# LPC55S14 register map
Vendor: nxp.com; File version: 1.0
CPU: CM33 r2p0, little endian, MPU, FPU, VTOR, 3 interrupt priority bits
Registers are 32-bit, read-write, reset 0x0 unless marked. A register's access mark holds for its fields unless they carry their own. Offsets are from the block's base; [hi:lo] are bit positions; lines under a group give offsets from that group; {n}, {i} and the like mark numbered series; 'fields as' and 'values as' point back to an identical list.

## I2S0 — I2S interface
Base 0x40086000; alternate view of FLEXCOMM0
Same registers: I2S1 0x40087000 (alternate view of FLEXCOMM1), I2S2 0x40088000 (alternate view of FLEXCOMM2), I2S3 0x40089000 (alternate view of FLEXCOMM3), I2S4 0x4008A000 (alternate view of FLEXCOMM4), I2S5 0x40096000 (alternate view of FLEXCOMM5), I2S6 0x40097000 (alternate view of FLEXCOMM6), I2S7 0x40098000 (alternate view of FLEXCOMM7)
{0x0+0x20*i} SECCHANNEL[{i}] (i=0..2) group
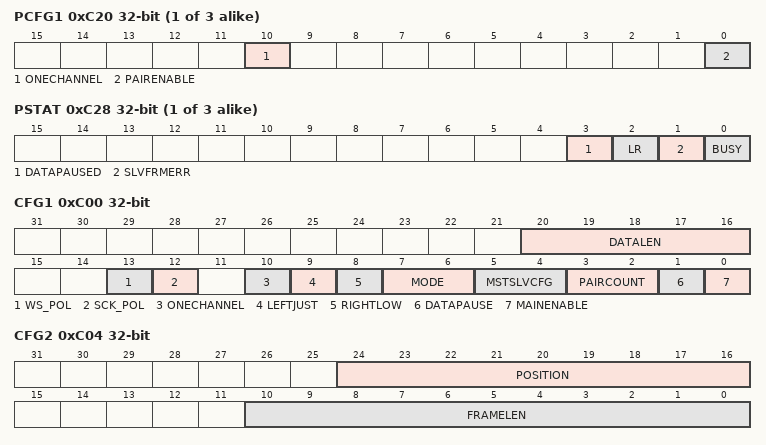
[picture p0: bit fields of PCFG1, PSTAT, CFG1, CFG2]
  0xC20 PCFG1 — Configuration register 1 for channel pair
    [10] ONECHANNEL — Single channel mode.
      0=STEREO (I2S data for this channel pair is treated as left and right channels.); 1=SINGLE (I2S data for this channel pair is treated as a single channel, functionally the left channel for this pair.)
    [0] PAIRENABLE — Enable for this channel pair.
      0=DISABLE (This I2S channel pair is disabled.); 1=ENABLE (This I2S channel pair is enabled.)
  0xC24 PCFG2 — Configuration register 2 for channel pair
    [24:16] POSITION — Data Position.
  0xC28 PSTAT — Status register for channel pair
    [3] DATAPAUSED ro — Data Paused status flag.
      0=PAUSE (Data is not currently paused.); 1=FORCE (A data pause has been requested and is now in force.)
    [2] LR — Left/Right indication.
    [1] SLVFRMERR — Save Frame Error flag.
    [0] BUSY — Busy status for this channel pair.
      0=IDLE (The transmitter/receiver for this channel pair is currently idle.); 1=PROCESSING (The transmitter/receiver for this channel pair is currently processing data.)
0xC00 CFG1 — Configuration register 1 for the primary channel pair.
  [20:16] DATALEN — Data Length, minus 1 encoded, defines the number of data bits to be transmitted or received for all I2S channel pairs in this Flexcomm. Note that data is only driven to or received from SDA for the number of bits defined by DATALEN. DATALEN is also used in these ways by the I2S: Determines the size of data transfers between the FIFO and the I2S serializer/deserializer. See FIFO buffer configurations and usage In mode 1, 2, and 3, determines the location of right data following left data in the frame. In mode 3 (where WS has a one data slot long pulse at the beginning of each data frame) determines the duration of the WS pulse. Values: 0x00 to 0x02 = not supported 0x03 = data is 4 bits in length 0x04 = data is 5 bits in length 0x1F = data is 32 bits in length
  [13] WS_POL — WS polarity.
    0=NOT_INVERTED (Data frames begin at a falling edge of WS (standard for classic I2S).); 1=INVERTED (WS is inverted, resulting in a data frame beginning at a rising edge of WS (standard for most 'non-classic' variations of I2S).)
  [12] SCK_POL — SCK polarity.
    0=FALLING_EDGE (Data is launched on SCK falling edges and sampled on SCK rising edges (standard for I2S).); 1=RISING_EDGE (Data is launched on SCK rising edges and sampled on SCK falling edges.)
  [10] ONECHANNEL — Single channel mode. Applies to both transmit and receive. This configuration bit applies only to the first I2S channel pair. Other channel pairs may select this mode independently in their separate CFG1 registers.
    0=DUAL_CHANNEL (I2S data for this channel pair is treated as left and right channels.); 1=SINGLE_CHANNEL (I2S data for this channel pair is treated as a single channel, functionally the left channel for this pair. In mode 0 only, the right side of the frame begins at POSITION = 0x100. This is because mode 0 makes a clear distinction between the left and right sides of the frame. When ONECHANNEL = 1, the single channel of data may be placed on the right by setting POSITION to 0x100 + the data position within the right side (e.g. 0x108 would place data starting at the 8th clock after the middle of the frame). In other modes, data for the single channel of data is placed at the clock defined by POSITION.)
  [9] LEFTJUST — Left Justify data.
    0=RIGHT_JUSTIFIED (Data is transferred between the FIFO and the I2S serializer/deserializer right justified, i.e. starting from bit 0 and continuing to the position defined by DATALEN. This would correspond to right justified data in the stream on the data bus.); 1=LEFT_JUSTIFIED (Data is transferred between the FIFO and the I2S serializer/deserializer left justified, i.e. starting from the MSB of the FIFO entry and continuing for the number of bits defined by DATALEN. This would correspond to left justified data in the stream on the data bus.)
  [8] RIGHTLOW — Right channel data is in the Low portion of FIFO data. Essentially, this swaps left and right channel data as it is transferred to or from the FIFO. This bit is not used if the data width is greater than 24 bits or if PDMDATA = 1. Note that if the ONECHANNEL field (bit 10 of this register) = 1, the one channel to be used is the nominally the left channel. POSITION can still place that data in the frame where right channel data is normally located. if all enabled channel pairs have ONECHANNEL = 1, then RIGHTLOW = 1 is not allowed.
    0=RIGHT_HIGH (The right channel is taken from the high part of the FIFO data. For example, when data is 16 bits, FIFO bits 31:16 are used for the right channel.); 1=RIGHT_LOW (The right channel is taken from the low part of the FIFO data. For example, when data is 16 bits, FIFO bits 15:0 are used for the right channel.)
  [7:6] MODE — Selects the basic I2S operating mode. Other configurations modify this to obtain all supported cases. See Formats and modes for examples.
    0=CLASSIC_MODE (I2S mode a.k.a. 'classic' mode. WS has a 50% duty cycle, with (for each enabled channel pair) one piece of left channel data occurring during the first phase, and one pieces of right channel data occurring during the second phase. In this mode, the data region begins one clock after the leading WS edge for the frame. For a 50% WS duty cycle, FRAMELEN must define an even number of I2S clocks for the frame. If FRAMELEN defines an odd number of clocks per frame, the extra clock will occur on the right.); 1=DSP_MODE_WS_50_DUTYCYCLE (DSP mode where WS has a 50% duty cycle. See remark for mode 0.); 2=DSP_MODE_WS_1_CLOCK (DSP mode where WS has a one clock long pulse at the beginning of each data frame.); 3=DSP_MODE_WS_1_DATA (DSP mode where WS has a one data slot long pulse at the beginning of each data frame.)
  [5:4] MSTSLVCFG — Master / slave configuration selection, determining how SCK and WS are used by all channel pairs in this Flexcomm.
    0=NORMAL_SLAVE_MODE (Normal slave mode, the default mode. SCK and WS are received from a master and used to transmit or receive data.); 1=WS_SYNC_MASTER (WS synchronized master. WS is received from another master and used to synchronize the generation of SCK, when divided from the Flexcomm function clock.); 2=MASTER_USING_SCK (Master using an existing SCK. SCK is received and used directly to generate WS, as well as transmitting or receiving data.); 3=NORMAL_MASTER (Normal master mode. SCK and WS are generated so they can be sent to one or more slave devices.)
  [3:2] PAIRCOUNT — Provides the number of I2S channel pairs in this Flexcomm This is a read-only field whose value may be different in other Flexcomms. 00 = there is 1 I2S channel pair in this Flexcomm. 01 = there are 2 I2S channel pairs in this Flexcomm. 10 = there are 3 I2S channel pairs in this Flexcomm. 11 = there are 4 I2S channel pairs in this Flexcomm.
    {v}=PAIRS_{v+1} ({v+1} I2S channel pairs in this flexcomm) (v=0..3)
  [1] DATAPAUSE — Data flow Pause. Allows pausing data flow between the I2S serializer/deserializer and the FIFO. This could be done in order to change streams, or while restarting after a data underflow or overflow. When paused, FIFO operations can be done without corrupting data that is in the process of being sent or received. Once a data pause has been requested, the interface may need to complete sending data that was in progress before interrupting the flow of data. Software must check that the pause is actually in effect before taking action. This is done by monitoring the DATAPAUSED flag in the STAT register. When DATAPAUSE is cleared, data transfer will resume at the beginning of the next frame.
    0=NORMAL (Normal operation, or resuming normal operation at the next frame if the I2S has already been paused.); 1=PAUSE (A pause in the data flow is being requested. It is in effect when DATAPAUSED in STAT = 1.)
  [0] MAINENABLE — Main enable for I 2S function in this Flexcomm
    0=DISABLED (All I 2S channel pairs in this Flexcomm are disabled and the internal state machines, counters, and flags are reset. No other channel pairs can be enabled.); 1=ENABLED (This I 2S channel pair is enabled. Other channel pairs in this Flexcomm may be enabled in their individual PAIRENABLE bits.)
0xC04 CFG2 (reset mask 0x1FF01FF) — Configuration register 2 for the primary channel pair.
  [24:16] POSITION — Data Position. Defines the location within the frame of the data for this channel pair. POSITION + DATALEN must be less than FRAMELEN. See Frame format. When MODE = 0, POSITION defines the location of data in both the left phase and right phase, starting one clock after the WS edge. In other modes, POSITION defines the location of data within the entire frame. ONECHANNEL = 1 while MODE = 0 is a special case, see the description of ONECHANNEL. The combination of DATALEN and the POSITION fields of all channel pairs must be made such that the channels do not overlap within the frame. 0x000 = data begins at bit position 0 (the first bit position) within the frame or WS phase. 0x001 = data begins at bit position 1 within the frame or WS phase. 0x002 = data begins at bit position 2 within the frame or WS phase.
  [10:0] FRAMELEN — Frame Length, minus 1 encoded, defines the number of clocks and data bits in the frames that this channel pair participates in. See Frame format. 0x000 to 0x002 = not supported 0x003 = frame is 4 bits in total length 0x004 = frame is 5 bits in total length 0x7FF = frame is 2048 bits in total length if FRAMELEN is an defines an odd length frame (e.g. 33 clocks) in mode 0 or 1, the extra clock appears in the right half. When MODE = 3, FRAMELEN must be larger than DATALEN in order for the WS pulse to be generated correctly.
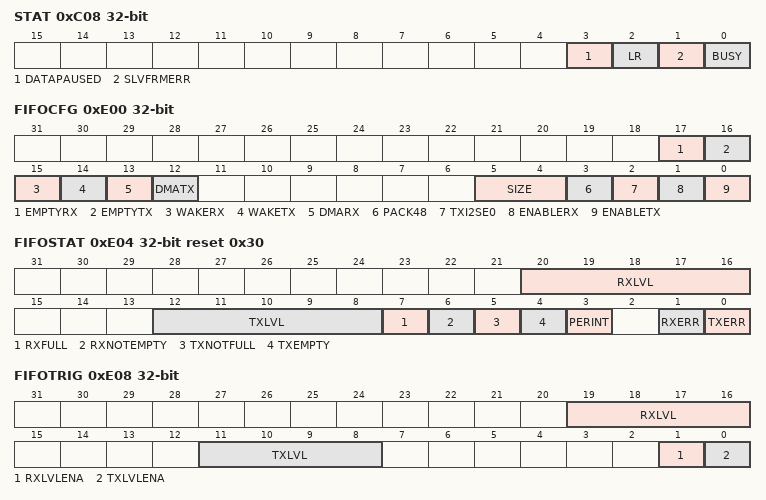
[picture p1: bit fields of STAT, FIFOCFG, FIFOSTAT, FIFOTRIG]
0xC08 STAT (reset mask 0xD) — Status register for the primary channel pair.
  [3] DATAPAUSED ro — Data Paused status flag. Applies to all I2S channels
    0=NOT_PAUSED (Data is not currently paused. A data pause may have been requested but is not yet in force, waiting for an allowed pause point. Refer to the description of the DATAPAUSE control bit in the CFG1 register.); 1=PAUSED (A data pause has been requested and is now in force.)
  [2] LR ro — Left/Right indication. This flag is considered to be a debugging aid and is not expected to be used by an I2S driver. Valid when one channel pair is busy. Indicates left or right data being processed for the currently busy channel pair.
    0=LEFT_CHANNEL; 1=RIGHT_CHANNEL
  [1] SLVFRMERR wo — Slave Frame Error flag. This applies when at least one channel pair is operating as a slave. An error indicates that the incoming WS signal did not transition as expected due to a mismatch between FRAMELEN and the actual incoming I2S stream.
    0=NO_ERROR (No error has been recorded.); 1=ERROR (An error has been recorded for some channel pair that is operating in slave mode. ERROR is cleared by writing a 1 to this bit position.)
  [0] BUSY ro — Busy status for the primary channel pair. Other BUSY flags may be found in the STAT register for each channel pair.
    0=IDLE (The transmitter/receiver for channel pair is currently idle.); 1=BUSY (The transmitter/receiver for channel pair is currently processing data.)
0xC1C DIV — Clock divider, used by all channel pairs.
  [11:0] DIV — This field controls how this I2S block uses the Flexcomm function clock. 0x000 = The Flexcomm function clock is used directly. 0x001 = The Flexcomm function clock is divided by 2. 0x002 = The Flexcomm function clock is divided by 3. 0xFFF = The Flexcomm function clock is divided by 4,096.
0xE00 FIFOCFG (reset mask 0x7F033) — FIFO configuration and enable register.
  [17] EMPTYRX — Empty command for the receive FIFO. When a 1 is written to this bit, the RX FIFO is emptied.
  [16] EMPTYTX — Empty command for the transmit FIFO. When a 1 is written to this bit, the TX FIFO is emptied.
  [15] WAKERX — Wake-up for receive FIFO level. This allows the device to be woken from reduced power modes (up to power-down, as long as the peripheral function works in that power mode) without enabling the TXLVL interrupt. Only DMA wakes up, processes data, and goes back to sleep. The CPU will remain stopped until woken by another cause, such as DMA completion. See Hardware Wake-up control register.
    0=DISABLED (Only enabled interrupts will wake up the device form reduced power modes.); 1=ENABLED (A device wake-up for DMA will occur if the receive FIFO level reaches the value specified by RXLVL in FIFOTRIG, even when the RXLVL interrupt is not enabled.)
  [14] WAKETX — Wake-up for transmit FIFO level. This allows the device to be woken from reduced power modes (up to power-down, as long as the peripheral function works in that power mode) without enabling the TXLVL interrupt. Only DMA wakes up, processes data, and goes back to sleep. The CPU will remain stopped until woken by another cause, such as DMA completion. See Hardware Wake-up control register.
    0=DISABLED (Only enabled interrupts will wake up the device form reduced power modes.); 1=ENABLED (A device wake-up for DMA will occur if the transmit FIFO level reaches the value specified by TXLVL in FIFOTRIG, even when the TXLVL interrupt is not enabled.)
  [13] DMARX — DMA configuration for receive.
    0=DISABLED (DMA is not used for the receive function.); 1=ENABLED (Trigger DMA for the receive function if the FIFO is not empty. Generally, data interrupts would be disabled if DMA is enabled.)
  [12] DMATX — DMA configuration for transmit.
    0=DISABLED (DMA is not used for the transmit function.); 1=ENABLED (Trigger DMA for the transmit function if the FIFO is not full. Generally, data interrupts would be disabled if DMA is enabled.)
  [5:4] SIZE ro — FIFO size configuration. This is a read-only field. 0x0 = FIFO is configured as 16 entries of 8 bits. 0x1, 0x2, 0x3 = not applicable to USART.
  [3] PACK48 — Packing format for 48-bit data. This relates to how data is entered into or taken from the FIFO by software or DMA.
    0=BIT_24 (48-bit I2S FIFO entries are handled as all 24-bit values.); 1=BIT_32_16 (48-bit I2S FIFO entries are handled as alternating 32-bit and 16-bit values.)
  [2] TXI2SE0 — Transmit I2S empty 0. Determines the value sent by the I2S in transmit mode if the TX FIFO becomes empty. This value is sent repeatedly until the I2S is paused, the error is cleared, new data is provided, and the I2S is un-paused.
    0=LAST_VALUE (If the TX FIFO becomes empty, the last value is sent. This setting may be used when the data length is 24 bits or less, or when MONO = 1 for this channel pair.); 1=ZERO (If the TX FIFO becomes empty, 0 is sent. Use if the data length is greater than 24 bits or if zero fill is preferred.)
  [1] ENABLERX — Enable the receive FIFO.
    0=DISABLED (The receive FIFO is not enabled.); 1=ENABLED (The receive FIFO is enabled.)
  [0] ENABLETX — Enable the transmit FIFO.
    0=DISABLED (The transmit FIFO is not enabled.); 1=ENABLED (The transmit FIFO is enabled.)
0xE04 FIFOSTAT reset 0x30 — FIFO status register.
  [20:16] RXLVL ro — Receive FIFO current level. A 0 means the RX FIFO is currently empty, and the RXFULL and RXNOTEMPTY flags will be 0. Other values tell how much data is actually in the RX FIFO at the point where the read occurs. If the RX FIFO is full, the RXFULL and RXNOTEMPTY flags will be 1.
  [12:8] TXLVL ro — Transmit FIFO current level. A 0 means the TX FIFO is currently empty, and the TXEMPTY and TXNOTFULL flags will be 1. Other values tell how much data is actually in the TX FIFO at the point where the read occurs. If the TX FIFO is full, the TXEMPTY and TXNOTFULL flags will be 0.
  [7] RXFULL ro — Receive FIFO full. When 1, the receive FIFO is full. Data needs to be read out to prevent the peripheral from causing an overflow.
  [6] RXNOTEMPTY ro — Receive FIFO not empty. When 1, the receive FIFO is not empty, so data can be read. When 0, the receive FIFO is empty.
  [5] TXNOTFULL ro — Transmit FIFO not full. When 1, the transmit FIFO is not full, so more data can be written. When 0, the transmit FIFO is full and another write would cause it to overflow.
  [4] TXEMPTY ro — Transmit FIFO empty. When 1, the transmit FIFO is empty. The peripheral may still be processing the last piece of data.
  [3] PERINT ro — Peripheral interrupt. When 1, this indicates that the peripheral function has asserted an interrupt. The details can be found by reading the peripheral's STAT register.
  [1] RXERR — RX FIFO error. Will be set if a receive FIFO overflow occurs, caused by software or DMA not emptying the FIFO fast enough. Cleared by writing a 1 to this bit.
  [0] TXERR — TX FIFO error. Will be set if a transmit FIFO error occurs. This could be an overflow caused by pushing data into a full FIFO, or by an underflow if the FIFO is empty when data is needed. Cleared by writing a 1 to this bit.
0xE08 FIFOTRIG — FIFO trigger settings for interrupt and DMA request.
  [19:16] RXLVL — Receive FIFO level trigger point. The RX FIFO level is checked when a new piece of data is received. This field is used only when RXLVLENA = 1. If enabled to do so, the FIFO level can wake up the device just enough to perform DMA, then return to the reduced power mode. See Hardware Wake-up control register. 0 = trigger when the RX FIFO has received one entry (is no longer empty). 1 = trigger when the RX FIFO has received two entries. 15 = trigger when the RX FIFO has received 16 entries (has become full).
  [11:8] TXLVL — Transmit FIFO level trigger point. This field is used only when TXLVLENA = 1. If enabled to do so, the FIFO level can wake up the device just enough to perform DMA, then return to the reduced power mode. See Hardware Wake-up control register. 0 = trigger when the TX FIFO becomes empty. 1 = trigger when the TX FIFO level decreases to one entry. 15 = trigger when the TX FIFO level decreases to 15 entries (is no longer full).
  [1] RXLVLENA — Receive FIFO level trigger enable. This trigger will become an interrupt if enabled in FIFOINTENSET, or a DMA trigger if DMARX in FIFOCFG is set.
    0=DISABLED (Receive FIFO level does not generate a FIFO level trigger.); 1=ENABLED (An trigger will be generated if the receive FIFO level reaches the value specified by the RXLVL field in this register.)
  [0] TXLVLENA — Transmit FIFO level trigger enable. This trigger will become an interrupt if enabled in FIFOINTENSET, or a DMA trigger if DMATX in FIFOCFG is set.
    0=DISABLED (Transmit FIFO level does not generate a FIFO level trigger.); 1=ENABLED (An trigger will be generated if the transmit FIFO level reaches the value specified by the TXLVL field in this register.)
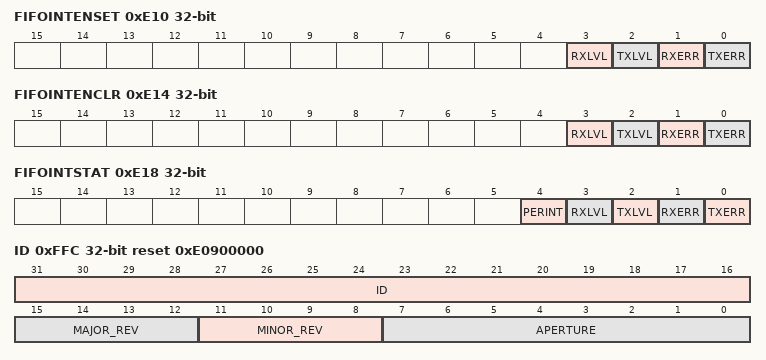
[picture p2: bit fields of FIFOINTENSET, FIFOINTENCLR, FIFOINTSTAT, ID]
0xE10 FIFOINTENSET — FIFO interrupt enable set (enable) and read register.
  [3] RXLVL — Determines whether an interrupt occurs when a the receive FIFO reaches the level specified by the TXLVL field in the FIFOTRIG register.
    0=DISABLED (No interrupt will be generated based on the RX FIFO level.); 1=ENABLED (If RXLVLENA in the FIFOTRIG register = 1, an interrupt will be generated when the when the RX FIFO level increases to the level specified by RXLVL in the FIFOTRIG register.)
  [2] TXLVL — Determines whether an interrupt occurs when a the transmit FIFO reaches the level specified by the TXLVL field in the FIFOTRIG register.
    0=DISABLED (No interrupt will be generated based on the TX FIFO level.); 1=ENABLED (If TXLVLENA in the FIFOTRIG register = 1, an interrupt will be generated when the TX FIFO level decreases to the level specified by TXLVL in the FIFOTRIG register.)
  [1] RXERR — Determines whether an interrupt occurs when a receive error occurs, based on the RXERR flag in the FIFOSTAT register.
    0=DISABLED (No interrupt will be generated for a receive error.); 1=ENABLED (An interrupt will be generated when a receive error occurs.)
  [0] TXERR — Determines whether an interrupt occurs when a transmit error occurs, based on the TXERR flag in the FIFOSTAT register.
    0=DISABLED (No interrupt will be generated for a transmit error.); 1=ENABLED (An interrupt will be generated when a transmit error occurs.)
0xE14 FIFOINTENCLR — FIFO interrupt enable clear (disable) and read register.
  [3] RXLVL — Writing one clears the corresponding bits in the FIFOINTENSET register.
  [2] TXLVL — Writing one clears the corresponding bits in the FIFOINTENSET register.
  [1] RXERR — Writing one clears the corresponding bits in the FIFOINTENSET register.
  [0] TXERR — Writing one clears the corresponding bits in the FIFOINTENSET register.
0xE18 FIFOINTSTAT ro — FIFO interrupt status register.
  [4] PERINT — Peripheral interrupt.
  [3] RXLVL — Receive FIFO level interrupt.
  [2] TXLVL — Transmit FIFO level interrupt.
  [1] RXERR — RX FIFO error.
  [0] TXERR — TX FIFO error.
0xE20 FIFOWR wo reset not defined — FIFO write data.
  [31:0] TXDATA — Transmit data to the FIFO. The number of bits used depends on configuration details.
0xE24 FIFOWR48H wo reset not defined — FIFO write data for upper data bits. May only be used if the I2S is configured for 2x 24-bit data and not using DMA.
  [23:0] TXDATA — Transmit data to the FIFO. Whether this register is used and the number of bits used depends on configuration details.
0xE30 FIFORD ro reset not defined — FIFO read data.
  [31:0] RXDATA — Received data from the FIFO. The number of bits used depends on configuration details.
0xE34 FIFORD48H ro — FIFO read data for upper data bits. May only be used if the I2S is configured for 2x 24-bit data and not using DMA.
  [23:0] RXDATA — Received data from the FIFO. Whether this register is used and the number of bits used depends on configuration details.
0xE40 FIFORDNOPOP ro reset not defined — FIFO data read with no FIFO pop.
  [31:0] RXDATA — Received data from the FIFO.
0xE44 FIFORD48HNOPOP ro — FIFO data read for upper data bits with no FIFO pop. May only be used if the I2S is configured for 2x 24-bit data and not using DMA.
  fields as FIFORD48H
0xE48 FIFOSIZE reset 0x8
  [4:0] FIFOSIZE ro — Provides the size of the FIFO for software. The size of the SPI FIFO is 8 entries.
0xFFC ID ro reset 0xE0900000 — I2S Module identification
  [31:16] ID — Unique module identifier for this IP block.
  [15:12] MAJOR_REV — Major revision of module implementation, starting at 0.
  [11:8] MINOR_REV — Minor revision of module implementation, starting at 0.
  [7:0] APERTURE — Aperture: encoded as (aperture size/4K) -1, so 0x00 means a 4K aperture.
